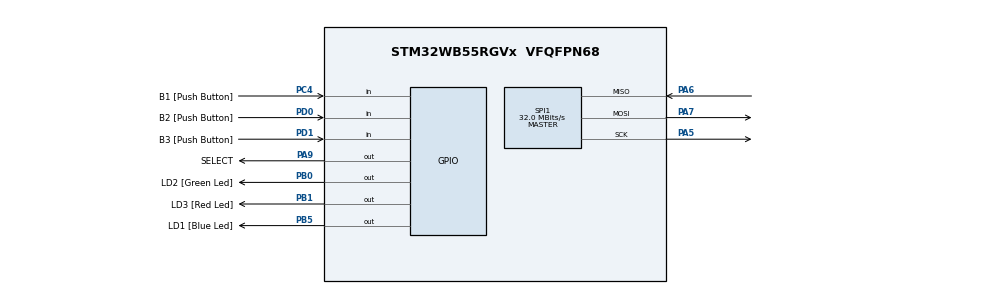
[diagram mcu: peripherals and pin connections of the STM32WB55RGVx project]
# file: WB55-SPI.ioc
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Dma.Request0=SPI1_RX
Dma.Request1=SPI1_TX
Dma.SPI1_RX.0.Direction=DMA_PERIPH_TO_MEMORY
Dma.SPI1_RX.0.EventEnable=DISABLE
Dma.SPI1_RX.0.Instance=DMA1_Channel1
Dma.SPI1_RX.0.MemDataAlignment=DMA_MDATAALIGN_BYTE
Dma.SPI1_RX.0.MemInc=DMA_MINC_ENABLE
Dma.SPI1_RX.0.Mode=DMA_NORMAL
Dma.SPI1_RX.0.PeriphDataAlignment=DMA_PDATAALIGN_BYTE
Dma.SPI1_RX.0.PeriphInc=DMA_PINC_DISABLE
Dma.SPI1_RX.0.Polarity=HAL_DMAMUX_REQ_GEN_RISING
Dma.SPI1_RX.0.Priority=DMA_PRIORITY_LOW
Dma.SPI1_RX.0.RequestNumber=1
Dma.SPI1_RX.0.SignalID=NONE
Dma.SPI1_RX.0.SyncEnable=DISABLE
Dma.SPI1_RX.0.SyncPolarity=HAL_DMAMUX_SYNC_NO_EVENT
Dma.SPI1_RX.0.SyncRequestNumber=1
Dma.SPI1_RX.0.SyncSignalID=NONE
Dma.SPI1_TX.1.Direction=DMA_MEMORY_TO_PERIPH
Dma.SPI1_TX.1.EventEnable=DISABLE
Dma.SPI1_TX.1.Instance=DMA1_Channel2
Dma.SPI1_TX.1.MemDataAlignment=DMA_MDATAALIGN_BYTE
Dma.SPI1_TX.1.MemInc=DMA_MINC_ENABLE
Dma.SPI1_TX.1.Mode=DMA_NORMAL
Dma.SPI1_TX.1.PeriphDataAlignment=DMA_PDATAALIGN_BYTE
Dma.SPI1_TX.1.PeriphInc=DMA_PINC_DISABLE
Dma.SPI1_TX.1.Polarity=HAL_DMAMUX_REQ_GEN_RISING
Dma.SPI1_TX.1.Priority=DMA_PRIORITY_LOW
Dma.SPI1_TX.1.RequestNumber=1
Dma.SPI1_TX.1.SignalID=NONE
Dma.SPI1_TX.1.SyncEnable=DISABLE
Dma.SPI1_TX.1.SyncPolarity=HAL_DMAMUX_SYNC_NO_EVENT
Dma.SPI1_TX.1.SyncRequestNumber=1
Dma.SPI1_TX.1.SyncSignalID=NONE
FREERTOS.Tasks01=defaultTask,24,128,StartDefaultTask,Default,NULL,Dynamic,NULL,NULL
Mcu.Family=STM32WB
Mcu.Name=STM32WB55RGVx
Mcu.Package=VFQFPN68
NVIC.DMA1_Channel1_IRQn=true\:5\:0\:false\:false\:true\:true\:false\:true
NVIC.DMA1_Channel2_IRQn=true\:5\:0\:false\:false\:true\:true\:false\:true
NVIC.PriorityGroup=NVIC_PRIORITYGROUP_4
NVIC.SPI1_IRQn=true\:5\:0\:false\:false\:true\:true\:true\:true
NVIC.TIM1_UP_TIM16_IRQn=true\:0\:0\:false\:false\:true\:false\:false\:true
NVIC.TimeBase=TIM1_UP_TIM16_IRQn
NVIC.TimeBaseIP=TIM16
OSC_IN.Signal=RCC_OSC_IN
OSC_OUT.Signal=RCC_OSC_OUT
PA11.Signal=USB_DM
PA12.Signal=USB_DP
PA13.GPIO_Label=JTMS
PA13.Signal=SYS_JTMS-SWDIO
PA14.GPIO_Label=JTCK
PA14.Signal=SYS_JTCK-SWCLK
PA5.GPIO_Speed=GPIO_SPEED_FREQ_HIGH
PA5.Mode=Full_Duplex_Master
PA5.Signal=SPI1_SCK
PA6.GPIO_Speed=GPIO_SPEED_FREQ_HIGH
PA6.Mode=Full_Duplex_Master
PA6.Signal=SPI1_MISO
PA7.GPIO_Speed=GPIO_SPEED_FREQ_HIGH
PA7.Mode=Full_Duplex_Master
PA7.Signal=SPI1_MOSI
PA9.GPIO_Label=SELECT
PA9.GPIO_Speed=GPIO_SPEED_FREQ_HIGH
PA9.Signal=GPIO_Output
PB0.GPIO_Label=LD2 [Green Led]
PB0.Signal=GPIO_Output
PB1.GPIO_Label=LD3 [Red Led]
PB1.Signal=GPIO_Output
PB3.GPIO_Label=JTDO
PB3.Signal=SYS_JTDO-SWO
PB5.GPIO_Label=LD1 [Blue Led]
PB5.Signal=GPIO_Output
PB6.GPIO_Label=STLINK_RX
PB6.Signal=USART1_TX
PB7.GPIO_Label=STLINK_TX
PB7.Signal=USART1_RX
PC13.Signal=SYS_WKUP2
PC14-OSC32_IN.Signal=RCC_OSC32_IN
PC15-OSC32_OUT.Signal=RCC_OSC32_OUT
PC4.GPIO_Label=B1 [Push Button]
PC4.Signal=GPIO_Input
PD0.GPIO_Label=B2 [Push Button]
PD0.Signal=GPIO_Input
PD1.GPIO_Label=B3 [Push Button]
PD1.Signal=GPIO_Input
ProjectManager.HeapSize=0x200
ProjectManager.StackSize=0x400
ProjectManager.TargetToolchain=STM32CubeIDE
RCC.ADCFreq_Value=16000000
RCC.AHB2CLKDivider=RCC_SYSCLK_DIV2
RCC.AHBFreq_Value=64000000
RCC.APB1Freq_Value=64000000
RCC.APB1TimFreq_Value=64000000
RCC.APB2Freq_Value=64000000
RCC.APB2TimFreq_Value=64000000
RCC.APB3Freq_Value=16000000
RCC.CortexFreq_Value=64000000
RCC.HCLKFreq_Value=64000000
RCC.HSE_VALUE=32000000
RCC.HSI48_VALUE=48000000
RCC.HSI_VALUE=16000000
RCC.LSE_VALUE=32768
RCC.PLLN=32
RCC.SMPSCLockSelectionVirtual=RCC_SMPSCLKSOURCE_HSI
RCC.SMPSCLockSelectionVirtualVirtual=RCC_SMPSCLKSOURCE_HSI
RCC.SMPSDivider=1
RCC.SYSCLKFreq_VALUE=64000000
RCC.SYSCLKSource=RCC_SYSCLKSOURCE_PLLCLK
RCC.USBFreq_Value=16000000
RCC.VCOOutputFreq_Value=128000000
SPI1.CalculateBaudRate=32.0 MBits/s
SPI1.DataSize=SPI_DATASIZE_8BIT
SPI1.Direction=SPI_DIRECTION_2LINES
SPI1.Mode=SPI_MODE_MASTER
SPI1.VirtualType=VM_MASTER
VP_FREERTOS_VS_CMSIS_V2.Mode=CMSIS_V2
VP_SYS_VS_tim16.Mode=TIM16
board=P-NUCLEO-WB55-Nucleo

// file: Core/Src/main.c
/* USER CODE BEGIN Header */
/**
  ******************************************************************************
  * @file           : main.c
  * @brief          : Main program body
  ******************************************************************************
  * @attention
  *
  * <h2><center>&copy; Copyright (c) 2020 STMicroelectronics.
  * All rights reserved.</center></h2>
  *
  * This software component is licensed by ST under BSD 3-Clause license,
  * the "License"; You may not use this file except in compliance with the
  * License. You may obtain a copy of the License at:
  *                        opensource.org/licenses/BSD-3-Clause
  *
  ******************************************************************************
  */
/* USER CODE END Header */

#include "main.h"
#include "cmsis_os.h"

SPI_HandleTypeDef hspi1;
DMA_HandleTypeDef hdma_spi1_rx;
DMA_HandleTypeDef hdma_spi1_tx;

/* Definitions for defaultTask */
osThreadId_t defaultTaskHandle;
const osThreadAttr_t defaultTask_attributes = {
  .name = "defaultTask",
  .priority = (osPriority_t) osPriorityNormal,
  .stack_size = 128 * 4
};

/* USER CODE BEGIN PV */
osThreadId_t ecatSOESHandle;
uint32_t ecatSOESTBuffer[1024];
StaticTask_t ecatSOESTControlBlock;
const osThreadAttr_t ecatSOEST_Attrbuttes = {
		.name = "ecatSOEST",
		.stack_mem = ecatSOESTBuffer,
		.stack_size = sizeof(ecatSOESTBuffer),
		.cb_mem = &ecatSOESTControlBlock,
		.cb_size = sizeof(ecatSOESTControlBlock),
		.priority = (osPriority_t) osPriorityHigh1,
};

void soes (void * arg);
/* USER CODE END PV */

void SystemClock_Config(void);
static void MX_GPIO_Init(void);
static void MX_DMA_Init(void);
static void MX_SPI1_Init(void);
void StartDefaultTask(void *argument);

int main(void)
{

  /* MCU Configuration--------------------------------------------------------*/

  /* Reset of all peripherals, Initializes the Flash interface and the Systick. */
  HAL_Init();

  /* Configure the system clock */
  SystemClock_Config();

  /* Initialize all configured peripherals */
  MX_GPIO_Init();
  MX_DMA_Init();
  MX_SPI1_Init();

  /* Init scheduler */
  osKernelInitialize();

  /* Create the thread(s) */
  /* creation of defaultTask */
  defaultTaskHandle = osThreadNew(StartDefaultTask, NULL, &defaultTask_attributes);

  /* USER CODE BEGIN RTOS_THREADS */
  /* add threads, ... */
  ecatSOESHandle = osThreadNew(soes, NULL, &ecatSOEST_Attrbuttes);
  ecat_SPIConfig(&hspi1);
  /* USER CODE END RTOS_THREADS */

  /* Start scheduler */
  osKernelStart();

  /* We should never get here as control is now taken by the scheduler */
  /* Infinite loop */
  while (1)
  {

  }
}

void SystemClock_Config(void)
{
  RCC_OscInitTypeDef RCC_OscInitStruct = {0};
  RCC_ClkInitTypeDef RCC_ClkInitStruct = {0};
  RCC_PeriphCLKInitTypeDef PeriphClkInitStruct = {0};

  /** Configure the main internal regulator output voltage
  */
  __HAL_PWR_VOLTAGESCALING_CONFIG(PWR_REGULATOR_VOLTAGE_SCALE1);
  /** Initializes the CPU, AHB and APB busses clocks
  */
  RCC_OscInitStruct.OscillatorType = RCC_OSCILLATORTYPE_HSI|RCC_OSCILLATORTYPE_MSI;
  RCC_OscInitStruct.HSIState = RCC_HSI_ON;
  RCC_OscInitStruct.MSIState = RCC_MSI_ON;
  RCC_OscInitStruct.HSICalibrationValue = RCC_HSICALIBRATION_DEFAULT;
  RCC_OscInitStruct.MSICalibrationValue = RCC_MSICALIBRATION_DEFAULT;
  RCC_OscInitStruct.MSIClockRange = RCC_MSIRANGE_6;
  RCC_OscInitStruct.PLL.PLLState = RCC_PLL_ON;
  RCC_OscInitStruct.PLL.PLLSource = RCC_PLLSOURCE_MSI;
  RCC_OscInitStruct.PLL.PLLM = RCC_PLLM_DIV1;
  RCC_OscInitStruct.PLL.PLLN = 32;
  RCC_OscInitStruct.PLL.PLLP = RCC_PLLP_DIV2;
  RCC_OscInitStruct.PLL.PLLR = RCC_PLLR_DIV2;
  RCC_OscInitStruct.PLL.PLLQ = RCC_PLLQ_DIV2;
  if (HAL_RCC_OscConfig(&RCC_OscInitStruct) != HAL_OK)
  {
    Error_Handler();
  }
  /** Configure the SYSCLKSource, HCLK, PCLK1 and PCLK2 clocks dividers
  */
  RCC_ClkInitStruct.ClockType = RCC_CLOCKTYPE_HCLK4|RCC_CLOCKTYPE_HCLK2
                              |RCC_CLOCKTYPE_HCLK|RCC_CLOCKTYPE_SYSCLK
                              |RCC_CLOCKTYPE_PCLK1|RCC_CLOCKTYPE_PCLK2;
  RCC_ClkInitStruct.SYSCLKSource = RCC_SYSCLKSOURCE_PLLCLK;
  RCC_ClkInitStruct.AHBCLKDivider = RCC_SYSCLK_DIV1;
  RCC_ClkInitStruct.APB1CLKDivider = RCC_HCLK_DIV1;
  RCC_ClkInitStruct.APB2CLKDivider = RCC_HCLK_DIV1;
  RCC_ClkInitStruct.AHBCLK2Divider = RCC_SYSCLK_DIV2;
  RCC_ClkInitStruct.AHBCLK4Divider = RCC_SYSCLK_DIV1;

  if (HAL_RCC_ClockConfig(&RCC_ClkInitStruct, FLASH_LATENCY_3) != HAL_OK)
  {
    Error_Handler();
  }
  /** Initializes the peripherals clocks
  */
  PeriphClkInitStruct.PeriphClockSelection = RCC_PERIPHCLK_SMPS;
  PeriphClkInitStruct.SmpsClockSelection = RCC_SMPSCLKSOURCE_HSI;
  PeriphClkInitStruct.SmpsDivSelection = RCC_SMPSCLKDIV_RANGE0;
  if (HAL_RCCEx_PeriphCLKConfig(&PeriphClkInitStruct) != HAL_OK)
  {
    Error_Handler();
  }
}

static void MX_SPI1_Init(void)
{

  /* SPI1 parameter configuration*/
  hspi1.Instance = SPI1;
  hspi1.Init.Mode = SPI_MODE_MASTER;
  hspi1.Init.Direction = SPI_DIRECTION_2LINES;
  hspi1.Init.DataSize = SPI_DATASIZE_8BIT;
  hspi1.Init.CLKPolarity = SPI_POLARITY_LOW;
  hspi1.Init.CLKPhase = SPI_PHASE_1EDGE;
  hspi1.Init.NSS = SPI_NSS_SOFT;
  hspi1.Init.BaudRatePrescaler = SPI_BAUDRATEPRESCALER_2;
  hspi1.Init.FirstBit = SPI_FIRSTBIT_MSB;
  hspi1.Init.TIMode = SPI_TIMODE_DISABLE;
  hspi1.Init.CRCCalculation = SPI_CRCCALCULATION_DISABLE;
  hspi1.Init.CRCPolynomial = 7;
  hspi1.Init.CRCLength = SPI_CRC_LENGTH_DATASIZE;
  hspi1.Init.NSSPMode = SPI_NSS_PULSE_ENABLE;
  if (HAL_SPI_Init(&hspi1) != HAL_OK)
  {
    Error_Handler();
  }

}

static void MX_DMA_Init(void)
{

  /* DMA controller clock enable */
  __HAL_RCC_DMAMUX1_CLK_ENABLE();
  __HAL_RCC_DMA1_CLK_ENABLE();

  /* DMA interrupt init */
  /* DMA1_Channel1_IRQn interrupt configuration */
  HAL_NVIC_SetPriority(DMA1_Channel1_IRQn, 5, 0);
  HAL_NVIC_EnableIRQ(DMA1_Channel1_IRQn);
  /* DMA1_Channel2_IRQn interrupt configuration */
  HAL_NVIC_SetPriority(DMA1_Channel2_IRQn, 5, 0);
  HAL_NVIC_EnableIRQ(DMA1_Channel2_IRQn);

}

static void MX_GPIO_Init(void)
{
  GPIO_InitTypeDef GPIO_InitStruct = {0};

  /* GPIO Ports Clock Enable */
  __HAL_RCC_GPIOC_CLK_ENABLE();
  __HAL_RCC_GPIOA_CLK_ENABLE();
  __HAL_RCC_GPIOB_CLK_ENABLE();
  __HAL_RCC_GPIOD_CLK_ENABLE();

  /*Configure GPIO pin Output Level */
  HAL_GPIO_WritePin(SELECT_GPIO_Port, SELECT_Pin, GPIO_PIN_RESET);

  /*Configure GPIO pin Output Level */
  HAL_GPIO_WritePin(GPIOB, LD2_Pin|LD3_Pin|LD1_Pin, GPIO_PIN_RESET);

  /*Configure GPIO pin : SELECT_Pin */
  GPIO_InitStruct.Pin = SELECT_Pin;
  GPIO_InitStruct.Mode = GPIO_MODE_OUTPUT_PP;
  GPIO_InitStruct.Pull = GPIO_NOPULL;
  GPIO_InitStruct.Speed = GPIO_SPEED_FREQ_HIGH;
  HAL_GPIO_Init(SELECT_GPIO_Port, &GPIO_InitStruct);

  /*Configure GPIO pin : B1_Pin */
  GPIO_InitStruct.Pin = B1_Pin;
  GPIO_InitStruct.Mode = GPIO_MODE_INPUT;
  GPIO_InitStruct.Pull = GPIO_NOPULL;
  HAL_GPIO_Init(B1_GPIO_Port, &GPIO_InitStruct);

  /*Configure GPIO pins : LD2_Pin LD3_Pin LD1_Pin */
  GPIO_InitStruct.Pin = LD2_Pin|LD3_Pin|LD1_Pin;
  GPIO_InitStruct.Mode = GPIO_MODE_OUTPUT_PP;
  GPIO_InitStruct.Pull = GPIO_NOPULL;
  GPIO_InitStruct.Speed = GPIO_SPEED_FREQ_LOW;
  HAL_GPIO_Init(GPIOB, &GPIO_InitStruct);

  /*Configure GPIO pins : PA11 PA12 */
  GPIO_InitStruct.Pin = GPIO_PIN_11|GPIO_PIN_12;
  GPIO_InitStruct.Mode = GPIO_MODE_AF_PP;
  GPIO_InitStruct.Pull = GPIO_NOPULL;
  GPIO_InitStruct.Speed = GPIO_SPEED_FREQ_LOW;
  GPIO_InitStruct.Alternate = GPIO_AF10_USB;
  HAL_GPIO_Init(GPIOA, &GPIO_InitStruct);

  /*Configure GPIO pins : B2_Pin B3_Pin */
  GPIO_InitStruct.Pin = B2_Pin|B3_Pin;
  GPIO_InitStruct.Mode = GPIO_MODE_INPUT;
  GPIO_InitStruct.Pull = GPIO_NOPULL;
  HAL_GPIO_Init(GPIOD, &GPIO_InitStruct);

  /*Configure GPIO pins : STLINK_RX_Pin STLINK_TX_Pin */
  GPIO_InitStruct.Pin = STLINK_RX_Pin|STLINK_TX_Pin;
  GPIO_InitStruct.Mode = GPIO_MODE_AF_PP;
  GPIO_InitStruct.Pull = GPIO_NOPULL;
  GPIO_InitStruct.Speed = GPIO_SPEED_FREQ_LOW;
  GPIO_InitStruct.Alternate = GPIO_AF7_USART1;
  HAL_GPIO_Init(GPIOB, &GPIO_InitStruct);

}

void StartDefaultTask(void *argument)
{
  for(;;)
  {
    osDelay(1);
  }
}

 /**
  * @brief  Period elapsed callback in non blocking mode
  * @note   This function is called  when TIM16 interrupt took place, inside
  * HAL_TIM_IRQHandler(). It makes a direct call to HAL_IncTick() to increment
  * a global variable "uwTick" used as application time base.
  * @param  htim : TIM handle
  * @retval None
  */
void HAL_TIM_PeriodElapsedCallback(TIM_HandleTypeDef *htim)
{
  if (htim->Instance == TIM16) {
    HAL_IncTick();
  }
}

void Error_Handler(void)
{
}

/************************ (C) COPYRIGHT STMicroelectronics *****END OF FILE****/
